# OCP_System_Reg_PRM register map
Vendor: Texas Instruments
Peripheral module from a debugger description file (folder omap36xx).
Registers are 32-bit, access not given, reset values left out (the file's numbers can be read two ways) unless marked. A register's access mark holds for its fields unless they carry their own. Offsets are as the file gives them; lines under a group give offsets from that group; [hi:lo] are bit positions; {n}, {i} and the like mark numbered series; 'fields as' and 'values as' point back to an identical list; <NAME> marks a mode.

## OCP_System_Reg_PRM
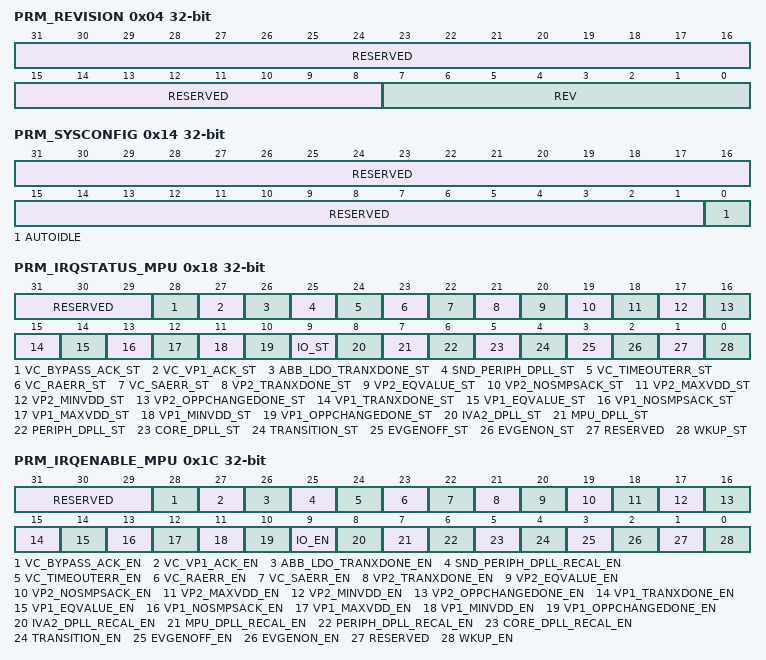
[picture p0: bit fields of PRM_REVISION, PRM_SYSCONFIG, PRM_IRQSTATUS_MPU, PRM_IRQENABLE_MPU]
0x04 PRM_REVISION ro — This register contains the IP revision code for the PRM part of the PRCM
  [31:8] RESERVED — Reads returns 0.
  [7:0] REV — IP revision[7:4] Major revision[3:0] Minor revisionExamples: 0x10 for 1.0, 0x21 for 2.1
0x14 PRM_SYSCONFIG access per field — This register controls the various parameters of the interface
  [31:1] RESERVED ro — Write 0s for future compatibility. Reads returns 0.
  [0] AUTOIDLE rw — Internal clock gating strategy (for the CM part of the PRCM)
    0=Interface clock is free-running; 1=Automatic clock gating strategy is enabled, based on the interface activity
0x18 PRM_IRQSTATUS_MPU — This interrupt status register regroups all the status of the module internal events that can generate an interrupt. Write 1 to a given bit resets this bit. This registers applies on the interrupt line 0 mapped to the MPU interrupt controller.
  [31:29] RESERVED ro — Write 0s for future compatibility. Reads returns 0.
  [28] VC_BYPASS_ACK_ST — Voltage controller's acknowledge to the bypass interface status. It is cleared by software. (access RW dual)
    0=VC_BYPASS_ACK_ST_0_r (Voltage controller's acknowledge to the bypass interface event is false.); 0=VC_BYPASS_ACK_ST_0_w (Status bit unchanged.); 1=VC_BYPASS_ACK_ST_1_r (Voltage controller's acknowledge to the bypass interface event is true (pending).); 1=VC_BYPASS_ACK_ST_1_w (Status bit is cleared to 0.)
  [27] VC_VP1_ACK_ST — Voltage controller's acknowledge to the VDD1 voltage processor status. It is cleared by software. (access RW dual)
    0=VC_VP1_ACK_ST_0_r (Voltage controller's acknowledge to the VDD1 voltage processor event is false.); 0=VC_VP1_ACK_ST_0_w (Status bit unchanged.); 1=VC_VP1_ACK_ST_1_r (Voltage controller's acknowledge to the VDD1 voltage processor event is true (pending).); 1=VC_VP1_ACK_ST_1_w (Status bit is cleared to 0.)
  [26] ABB_LDO_TRANXDONE_ST — ABB LDO transaction completion status. This status is set when a software-initiated transaction is completed in ABB LDO (active mode transition only). It is cleared by software. (access RW dual)
    0=ABB_LDO_TRANXDONE_ST_0_r (ABB LDO transaction done event is false.); 0=ABB_LDO_TRANXDONE_ST_0_w (Status bit unchanged.); 1=ABB_LDO_TRANXDONE_ST_1_r (ABB LDO transaction done event is true (pending).); 1=ABB_LDO_TRANXDONE_ST_1_w (Status bit is cleared to 0.)
  [25] SND_PERIPH_DPLL_ST rw — DPLL5 recalibration event status
    0=SND_PERIPH_DPLL_ST_0_r (DPLL5 recalibration event is false); 0=SND_PERIPH_DPLL_ST_0_w (Status bit unchanged); 1=SND_PERIPH_DPLL_ST_1_r (DPLL5 recalibration event is true (pending)); 1=SND_PERIPH_DPLL_ST_1_w (Status bit is cleared to 0.)
  [24] VC_TIMEOUTERR_ST rw — Voltage Controller timeout error event status
    0=VC_TIMEOUTERR_ST_0_r (Voltage Controller timeout error event is false); 0=VC_TIMEOUTERR_ST_0_w (Status bit unchanged); 1=VC_TIMEOUTERR_ST_1_r (Voltage Controller timeout error event is true (pending)); 1=VC_TIMEOUTERR_ST_1_w (Status bit is cleared to 0.)
  [23] VC_RAERR_ST rw — Voltage Controller register address acknowledge error event status
    0=VC_RAERR_ST_0_r (Voltage Controller register address acknowledge error event is false); 0=VC_RAERR_ST_0_w (Status bit unchanged); 1=VC_RAERR_ST_1_r (Voltage Controller register address acknowledge error event is true (pending)); 1=VC_RAERR_ST_1_w (Status bit is cleared to 0.)
  [22] VC_SAERR_ST rw — Voltage Controller slave address acknowledge error event status
    0=VC_SAERR_ST_0_r (Voltage Controller slave address acknowledge error event is false); 0=VC_SAERR_ST_0_w (Status bit unchanged); 1=VC_SAERR_ST_1_r (Voltage Controller slave address acknowledge error event is true (pending)); 1=VC_SAERR_ST_1_w (Status bit is cleared to 0.)
  [21] VP2_TRANXDONE_ST rw — Voltage Processor 2 transaction completion status. This status is set when a transaction is completed in the voltage processor. It is cleared by software.
    0=VP2_TRANXDONE_ST_0_r (Voltage Processor 2 transaction done event is false); 0=VP2_TRANXDONE_ST_0_w (Status bit unchanged); 1=VP2_TRANXDONE_ST_1_r (Voltage Processor 2 transaction done event is true (pending)); 1=VP2_TRANXDONE_ST_1_w (Status bit is cleared to 0.)
  [20] VP2_EQVALUE_ST rw — Voltage Processor 2 voltage value change event. This status is set when an update has been requested but the new voltage value is the same as the current SMPS voltage value. It is cleared by software.
    0=VP2_EQVALUE_ST_0_r (Voltage Processor 2 no voltage value change event is false); 0=VP2_EQVALUE_ST_0_w (Status bit unchanged); 1=VP2_EQVALUE_ST_1_r (Voltage Processor 2 no voltage value change event is true (pending)); 1=VP2_EQVALUE_ST_1_w (Status bit is cleared to 0.)
  [19] VP2_NOSMPSACK_ST rw — Voltage Processor 2 timeout event status. This status is set when the timeout occured before the SMPS acknowledge. It is cleared by SW.
    0=VP2_NOSMPSACK_ST_0_r (Voltage Processor 2 timeout event is false); 0=VP2_NOSMPSACK_ST_0_w (Status bit unchanged); 1=VP2_NOSMPSACK_ST_1_r (Voltage Processor 2 timeout event is true (pending)); 1=VP2_NOSMPSACK_ST_1_w (Status bit is cleared to 0.)
  [18] VP2_MAXVDD_ST rw — Voltage Processor 2 voltage higher limit event status. This status is set when the voltage higher limit is reached. It is cleared by SW.
    0=VP2_MAXVDD_ST_0_r (Voltage Processor 2 voltage higher limit event is false); 0=VP2_MAXVDD_ST_0_w (Status bit unchanged); 1=VP2_MAXVDD_ST_1_r (Voltage Processor 2 voltage higher limit event is true (pending)); 1=VP2_MAXVDD_ST_1_w (Status bit is cleared to 0.)
  [17] VP2_MINVDD_ST rw — Voltage Processor 2 voltage lower limit event status. This status is set when the voltage lower limit is reached. It is cleared by SW.
    0=VP2_MINVDD_ST_0_r (Voltage Processor 2 voltage lower limit event is false); 0=VP2_MINVDD_ST_0_w (Status bit unchanged); 1=VP2_MINVDD_ST_1_r (Voltage Processor 2 voltage lower limit event is true (pending)); 1=VP2_MINVDD_ST_1_w (Status bit is cleared to 0.)
  [16] VP2_OPPCHANGEDONE_ST rw — Voltage Processor 2 OPP change done status.
    0=VP2_OPPCHANGEDONE_ST_0_r (Voltage Processor 2 OPP change done event is false); 0=VP2_OPPCHANGEDONE_ST_0_w (Status bit unchanged); 1=VP2_OPPCHANGEDONE_ST_1_r (Voltage Processor 2 OPP change done event is true (pending)); 1=VP2_OPPCHANGEDONE_ST_1_w (Status bit is cleared to 0.)
  [15] VP1_TRANXDONE_ST rw — Voltage Processor 1 transaction completion status. This status is set when a transaction is completed in the voltage processor. It is cleared by SW.
    0=VP1_TRANXDONE_ST_0_r (Voltage Processor 1 transaction done event is false); 0=VP1_TRANXDONE_ST_0_w (Status bit unchanged); 1=VP1_TRANXDONE_ST_1_r (Voltage Processor 1 transaction done event is true (pending)); 1=VP1_TRANXDONE_ST_1_w (Status bit is cleared to 0.)
  [14] VP1_EQVALUE_ST rw — Voltage Processor 1 voltage value change event. This status is set when an update has been requested but the new voltage value is the same as the current SMPS voltage value. It is cleared by SW.
    0=VP1_EQVALUE_ST_0_r (Voltage Processor 1 no voltage value change event is false); 0=VP1_EQVALUE_ST_0_w (Status bit unchanged); 1=VP1_EQVALUE_ST_1_r (Voltage Processor 1 no voltage value change event is true (pending)); 1=VP1_EQVALUE_ST_1_w (Status bit is cleared to 0.)
  [13] VP1_NOSMPSACK_ST rw — Voltage Processor 1 timeout event status. This status is set when the timeout occured before the SMPS acknowledge. It is cleared by SW.
    0=VP1_NOSMPSACK_ST_0_r (Voltage Processor 1 timeout event is false); 0=VP1_NOSMPSACK_ST_0_w (Status bit unchanged); 1=VP1_NOSMPSACK_ST_1_r (Voltage Processor 1 timeout event is true (pending)); 1=VP1_NOSMPSACK_ST_1_w (Status bit is cleared to 0.)
  [12] VP1_MAXVDD_ST rw — Voltage Processor 1 voltage higher limit event status. This status is set when the voltage higher limit is reached. It is cleared by SW.
    0=VP1_MAXVDD_ST_0_r (Voltage Processor 1 voltage higher limit event is false); 0=VP1_MAXVDD_ST_0_w (Status bit unchanged); 1=VP1_MAXVDD_ST_1_r (Voltage Processor 1 voltage higher limit event is true (pending)); 1=VP1_MAXVDD_ST_1_w (Status bit is cleared to 0.)
  [11] VP1_MINVDD_ST rw — Voltage Processor 1 voltage lower limit event status. This status is set when the voltage lower limit is reached. It is cleared by SW.
    0=VP1_MINVDD_ST_0_r (Voltage Processor 1 voltage lower limit event is false); 0=VP1_MINVDD_ST_0_w (Status bit unchanged); 1=VP1_MINVDD_ST_1_r (Voltage Processor 1 voltage lower limit event is true (pending)); 1=VP1_MINVDD_ST_1_w (Status bit is cleared to 0.)
  [10] VP1_OPPCHANGEDONE_ST rw — Voltage Processor 1 OPP change done status.
    0=VP1_OPPCHANGEDONE_ST_0_r (Voltage Processor 1 OPP change done event is false); 0=VP1_OPPCHANGEDONE_ST_0_w (Status bit unchanged); 1=VP1_OPPCHANGEDONE_ST_1_r (Voltage Processor 1 OPP change done event is true (pending)); 1=VP1_OPPCHANGEDONE_ST_1_w (Status bit is cleared to 0.)
  [9] IO_ST rw — IO pad event status
    0=IO_ST_0_r (IO pad event is false); 0=IO_ST_0_w (Status bit unchanged); 1=IO_ST_1_r (IO pad event is true (pending)); 1=IO_ST_1_w (Status bit is cleared to 0.)
  [8] IVA2_DPLL_ST rw — IVA2 DPLL recalibration event status
    0=IVA2_DPLL_ST_0_r (IVA2 DPLL recalibration event is false); 0=IVA2_DPLL_ST_0_w (Status bit unchanged); 1=IVA2_DPLL_ST_1_r (IVA2 DPLL recalibration event is true (pending)); 1=IVA2_DPLL_ST_1_w (Status bit is cleared to 0.)
  [7] MPU_DPLL_ST rw — DPLL1 recalibration event status
    0=MPU_DPLL_ST_0_r (DPLL1 recalibration event is false); 0=MPU_DPLL_ST_0_w (Status bit unchanged); 1=MPU_DPLL_ST_1_r (DPLL1 recalibration event is true (pending)); 1=MPU_DPLL_ST_1_w (Status bit is cleared to 0.)
  [6] PERIPH_DPLL_ST rw — DPLL4 recalibration event status
    0=PERIPH_DPLL_ST_0_r (DPLL4 recalibration event is false); 0=PERIPH_DPLL_ST_0_w (Status bit unchanged); 1=PERIPH_DPLL_ST_1_r (DPLL4 recalibration event is true (pending)); 1=PERIPH_DPLL_ST_1_w (Status bit is cleared to 0.)
  [5] CORE_DPLL_ST rw — DPLL3 recalibration event status
    0=CORE_DPLL_ST_0_r (DPLL3 recalibration event is false); 0=CORE_DPLL_ST_0_w (Status bit unchanged); 1=CORE_DPLL_ST_1_r (DPLL3 recalibration event is true (pending)); 1=CORE_DPLL_ST_1_w (Status bit is cleared to 0.)
  [4] TRANSITION_ST rw — Software supervised transition completed event status
    0=TRANSITION_ST_0_r (Software supervised transition completed event is false); 0=TRANSITION_ST_0_w (Status bit unchanged); 1=TRANSITION_ST_1_r (Software supervised transition completed event is true (pending)); 1=TRANSITION_ST_1_w (Status bit is cleared to 0.)
  [3] EVGENOFF_ST rw — Event Generator endOFFtime status
    0=EVGENOFF_ST_0_r (End of OFF time event is false); 0=EVGENOFF_ST_0_w (Status bit unchanged); 1=EVGENOFF_ST_1_r (End of OFF time event is true (pending)); 1=EVGENOFF_ST_1_w (Status bit is cleared to 0.)
  [2] EVGENON_ST rw — Event Generator endONtime status
    0=EVGENON_ST_0_r (End of ON time event is false); 0=EVGENON_ST_0_w (Status bit unchanged); 1=EVGENON_ST_1_r (End of ON time event is true (pending)); 1=EVGENON_ST_1_w (Status bit is cleared to 0.)
  [1] RESERVED ro — Write 0s for future compatibility. Reads returns 0.
  [0] WKUP_ST rw — MPU peripherals group wake-up event status
    0=WKUP_ST_0_r (Wake-up event is false); 0=WKUP_ST_0_w (Status bit unchanged); 1=WKUP_ST_1_r (Wake-up event is true (pending)); 1=WKUP_ST_1_w (Status bit is cleared to 0.)
0x1C PRM_IRQENABLE_MPU — The interrupt enable register allows masking/unmasking the module internal sources of interrupt, on a event-by-event basis. This registers applies on the interrupt line 0 mapped to the MPU interrupt controller.
  [31:29] RESERVED ro — Write 0s for future compatibility. Reads returns 0.
  [28] VC_BYPASS_ACK_EN — Voltage controller's acknowledge to the bypass interface mask. (access RWdual)
    0=Voltage controller's acknowledge to the bypass interface event is masked; 1=Voltage controller's acknowledge to the bypass interface event generates an interrupt
  [27] VC_VP1_ACK_EN — Voltage controller's acknowledge to the VDD1 voltage processor mask. (access RWdual)
    0=Voltage controller's acknowledge to the VDD1 voltage processor event is masked; 1=Voltage controller's acknowledge to the VDD1 voltage processor event generates an interrupt
  [26] ABB_LDO_TRANXDONE_EN — ABB LDO transaction done mask. (access RWdual)
    0=ABB LDO transaction done event is masked; 1=ABB LDO transaction done event generates an interrupt
  [25] SND_PERIPH_DPLL_RECAL_EN rw — DPLL5 recalibration mask
    0=DPLL5 recalibration event is masked; 1=DPLL5 recalibration event generates an interrupt
  [24] VC_TIMEOUTERR_EN rw — Voltage Controller timeout error mask.
    0=Voltage Controller timeout error event is masked; 1=Voltage Controller timeout error event generates an interrupt
  [23] VC_RAERR_EN rw — Voltage Controller register address acknowledge error mask.
    0=Voltage Controller register address acknowledge error event is masked; 1=Voltage Controller register address acknowledge error event generates an interrupt
  [22] VC_SAERR_EN rw — Voltage Controller slave address acknowledge error mask.
    0=Voltage Controller slave address acknowledge error event is masked; 1=Voltage Controller slave address acknowledge error event generates an interrupt
  [21] VP2_TRANXDONE_EN rw — Voltage Processor 2 transaction done mask.
    0=Voltage Processor 2 transaction done event is masked; 1=Voltage Processor 2 transaction done event generates an interrupt
  [20] VP2_EQVALUE_EN rw — Voltage Processor 2 voltage value change mask.
    0=Voltage Processor 2 voltage value change event is masked; 1=Voltage Processor 2 voltage value change event generates an interrupt
  [19] VP2_NOSMPSACK_EN rw — Voltage Processor 2 timeout mask.
    0=Voltage Processor 2 timeout event is masked; 1=Voltage Processor 2 timeout event generates an interrupt
  [18] VP2_MAXVDD_EN rw — Voltage Processor 2 higher voltage limit mask.
    0=Voltage Processor 2 higher voltage limit event is masked; 1=Voltage Processor 2 higher voltage limit event generates an interrupt
  [17] VP2_MINVDD_EN rw — Voltage Processor 2 lower voltage limit mask.
    0=Voltage Processor 2 lower voltage limit event is masked; 1=Voltage Processor 2 lower voltage limit event generates an interrupt
  [16] VP2_OPPCHANGEDONE_EN rw — Voltage Processor 2 OPP change done mask.
    0=Voltage Processor 2 OPPChangeDone event is masked; 1=Voltage Processor 2 OPPChangeDone event generates an interrupt
  [15] VP1_TRANXDONE_EN rw — Voltage Processor 1 transaction done mask.
    0=Voltage Processor 1 transaction done event is masked; 1=Voltage Processor 1 transaction done event generates an interrupt
  [14] VP1_EQVALUE_EN rw — Voltage Processor 1 voltage value change mask.
    0=Voltage Processor 1 voltage value change event is masked; 1=Voltage Processor 1 voltage value change event generates an interrupt
  [13] VP1_NOSMPSACK_EN rw — Voltage Processor 1 timeout mask.
    0=Voltage Processor 1 timeout event is masked; 1=Voltage Processor 1 timeout event generates an interrupt
  [12] VP1_MAXVDD_EN rw — Voltage Processor 1 voltage higher limit mask.
    0=Voltage Processor 1 voltage higher limit event is masked; 1=Voltage Processor 1 voltage higher limit event generates an interrupt
  [11] VP1_MINVDD_EN rw — Voltage Processor 1 voltage lower limit mask.
    0=Voltage Processor 1 voltage lower limit event is masked; 1=Voltage Processor 1 voltage lower limit event generates an interrupt
  [10] VP1_OPPCHANGEDONE_EN rw — Voltage Processor 1 OPP change done mask.
    0=Voltage Processor 1 OPPChangeDone event is masked; 1=Voltage Processor 1 OPPChangeDone event generates an interrupt
  [9] IO_EN rw — IO pad event mask
    0=IO pad event is masked; 1=IO pad event generates an interrupt
  [8] IVA2_DPLL_RECAL_EN rw — IVA2 DPLL recalibration mask
    0=IVA2 DPLL recalibration event is masked; 1=IVA2 DPLL recalibration event generates an interrupt
  [7] MPU_DPLL_RECAL_EN rw — DPLL1 recalibration mask
    0=DPLL1 recalibration event is masked; 1=DPLL1 recalibration event generates an interrupt
  [6] PERIPH_DPLL_RECAL_EN rw — DPLL4 recalibration mask
    0=DPLL4 recalibration event is masked; 1=DPLL4 recalibration event generates an interrupt
  [5] CORE_DPLL_RECAL_EN rw — DPLL3 recalibration mask
    0=DPLL3 recalibration event is masked; 1=DPLL3 recalibration event generates an interrupt
  [4] TRANSITION_EN rw — Software supervised transition completed event mask
    0=Software supervised transition completed event is masked; 1=Software supervised transition completed event generates an interrupt
  [3] EVGENOFF_EN rw — Event Generator endOFFtime mask
    0=End of OFF time event is masked; 1=End of OFF time event generates an interrupt
  [2] EVGENON_EN rw — Event Generator endONtime mask
    0=End of ON time event is masked; 1=End of ON time event generates an interrupt
  [1] RESERVED ro — Write 0s for future compatibility. Reads returns 0.
  [0] WKUP_EN rw — MPU peripherals group wake-up event mask
    0=MPU peripherals group wake-up event is masked; 1=MPU peripherals group wake-up event generates an interrupt
